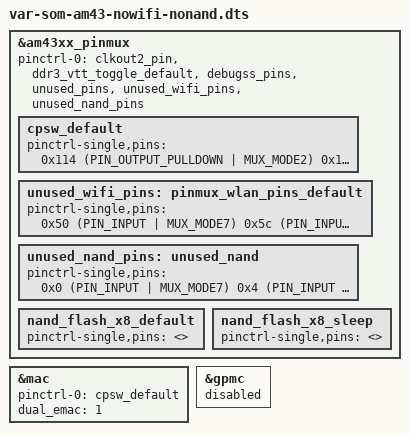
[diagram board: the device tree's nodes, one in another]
/*
 * Copyright (C) 2014 Variscite LTD - http://www.variscite.com/
 *
 * This program is free software; you can redistribute it and/or modify
 * it under the terms of the GNU General Public License version 2 as
 * published by the Free Software Foundation.
 */

/* VAR-SOM-AM43 */

#include "var-som-am43.dtsi"


&am43xx_pinmux {
	pinctrl-0 = <&clkout2_pin &ddr3_vtt_toggle_default &debugss_pins &unused_pins /* &lcd_pins */ &unused_wifi_pins &unused_nand_pins>;

	cpsw_default: cpsw_default {
		pinctrl-single,pins = <
			/* Slave 1 */
			0x114 (PIN_OUTPUT_PULLDOWN | MUX_MODE2)	/* mii1_txen.rgmii1_txen */
			0x118 (PIN_INPUT_PULLDOWN | MUX_MODE2)	/* mii1_rxdv.rgmii1_rxctl */
			0x11c (PIN_OUTPUT_PULLDOWN | MUX_MODE2)	/* mii1_txd1.rgmii1_txd3 */
			0x120 (PIN_OUTPUT_PULLDOWN | MUX_MODE2)	/* mii1_txd0.rgmii1_txd2 */
			0x124 (PIN_OUTPUT_PULLDOWN | MUX_MODE2)	/* mii1_txd1.rgmii1_txd1 */
			0x128 (PIN_OUTPUT_PULLDOWN | MUX_MODE2)	/* mii1_txd0.rgmii1_txd0 */
			0x12c (PIN_OUTPUT_PULLDOWN | MUX_MODE2)	/* mii1_txclk.rmii1_tclk */
			0x130 (PIN_INPUT_PULLDOWN | MUX_MODE2)	/* mii1_rxclk.rmii1_rclk */
			0x134 (PIN_INPUT_PULLDOWN | MUX_MODE2)	/* mii1_rxd1.rgmii1_rxd3 */
			0x138 (PIN_INPUT_PULLDOWN | MUX_MODE2)	/* mii1_rxd0.rgmii1_rxd2 */
			0x13c (PIN_INPUT_PULLDOWN | MUX_MODE2)	/* mii1_rxd1.rgmii1_rxd1 */
			0x140 (PIN_INPUT_PULLDOWN | MUX_MODE2)	/* mii1_rxd0.rgmii1_rxd0 */

			0x38 (PIN_OUTPUT_PULLUP | MUX_MODE7)   /* PHY reset */
		>;
	};

	unused_wifi_pins: pinmux_wlan_pins_default {
		pinctrl-single,pins = <
			0x50 (PIN_INPUT  | MUX_MODE7)
			0x5c (PIN_INPUT  | MUX_MODE7)
			0x40 (PIN_INPUT  | MUX_MODE7)
			0x6c (PIN_INPUT  | MUX_MODE7)
			0x68 (PIN_INPUT  | MUX_MODE7)
			0x64 (PIN_INPUT  | MUX_MODE7)
			0x60 (PIN_INPUT  | MUX_MODE7)
			0x8c (PIN_INPUT  | MUX_MODE7)
			0x88 (PIN_INPUT  | MUX_MODE7)
			0x44 (PIN_INPUT  | MUX_MODE7)
			0x48 (PIN_INPUT  | MUX_MODE7)
			0x4c (PIN_INPUT  | MUX_MODE7)
			0x78 (PIN_INPUT  | MUX_MODE7)
			0x54 (PIN_INPUT  | MUX_MODE7)
			0x58 (PIN_INPUT  | MUX_MODE7)
		>;
	};

	unused_nand_pins: unused_nand {
		pinctrl-single,pins = <
			0x0  (PIN_INPUT  | MUX_MODE7)	/* gpmc_ad0.gpmc_ad0 */
			0x4  (PIN_INPUT  | MUX_MODE7)	/* gpmc_ad1.gpmc_ad1 */
			0x8  (PIN_INPUT  | MUX_MODE7)	/* gpmc_ad2.gpmc_ad2 */
			0xc  (PIN_INPUT  | MUX_MODE7)	/* gpmc_ad3.gpmc_ad3 */
			0x10 (PIN_INPUT  | MUX_MODE7)	/* gpmc_ad4.gpmc_ad4 */
			0x14 (PIN_INPUT  | MUX_MODE7)	/* gpmc_ad5.gpmc_ad5 */
			0x18 (PIN_INPUT  | MUX_MODE7)	/* gpmc_ad6.gpmc_ad6 */
			0x1c (PIN_INPUT  | MUX_MODE7)	/* gpmc_ad7.gpmc_ad7 */
			0x98 (PIN_INPUT  | MUX_MODE7)		/* gpmc_wen.gpmc_wen */
			0x9c (PIN_INPUT  | MUX_MODE7)		/* gpmc_be0n_cle.gpmc_be0n_cle */
			0x90 (PIN_INPUT  | MUX_MODE7)		/* gpmc_advn_ale.gpmc_advn_ale */
			0x94 (PIN_INPUT  | MUX_MODE7)		/* gpmc_oen_ren.gpmc_oen_ren */
			0x70 (PIN_INPUT  | MUX_MODE7)	/* gpmc_wait0.gpmc_wait0 */
			0x74 (PIN_INPUT  | MUX_MODE7)	/* gpmc_wpn.gpmc_wpn */
		>;
	};

	nand_flash_x8_default: nand_flash_x8_default {
		pinctrl-single,pins = <>;
	};

	nand_flash_x8_sleep: nand_flash_x8_sleep {
		pinctrl-single,pins = <>;
	};


};

&mac {
	pinctrl-names = "default";
	pinctrl-0 = <&cpsw_default>;
	dual_emac = <1>;
	status = "okay";
};

&gpmc {
	status = "disabled";
};


